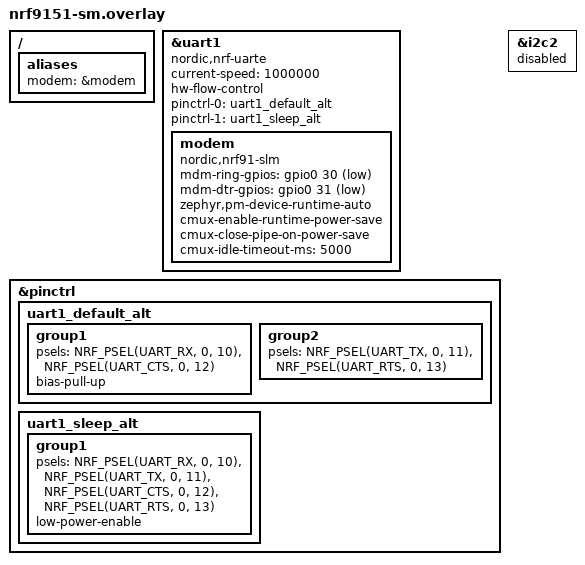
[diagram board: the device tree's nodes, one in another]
/*
 * Copyright (c) 2026 Nordic Semiconductor ASA
 *
 * SPDX-License-Identifier: LicenseRef-Nordic-5-Clause
 */
/ {
	aliases {
		modem = &modem;
	};
};

&uart1 {
	compatible = "nordic,nrf-uarte";
	current-speed = <1000000>;
	hw-flow-control;
	status = "okay";

	pinctrl-0 = <&uart1_default_alt>;
	pinctrl-1 = <&uart1_sleep_alt>;
	pinctrl-names = "default", "sleep";

	modem: modem {
		compatible = "nordic,nrf91-slm";
		status = "okay";
		mdm-ring-gpios = <&gpio0 30 (GPIO_ACTIVE_LOW | GPIO_PULL_UP)>;
		mdm-dtr-gpios = <&gpio0 31 GPIO_ACTIVE_LOW>;
		zephyr,pm-device-runtime-auto;
		cmux-enable-runtime-power-save;
		cmux-close-pipe-on-power-save;
		cmux-idle-timeout-ms = <5000>;
	};
};

&pinctrl {
	uart1_default_alt: uart1_default_alt {
		group1 {
			psels = <NRF_PSEL(UART_RX, 0, 10)>,
				<NRF_PSEL(UART_CTS, 0, 12)>;
			bias-pull-up;
		};

		group2 {
			psels = <NRF_PSEL(UART_TX, 0, 11)>,
				<NRF_PSEL(UART_RTS, 0, 13)>;
		};
	};

	uart1_sleep_alt: uart1_sleep_alt {
		group1 {
			psels = <NRF_PSEL(UART_RX, 0, 10)>,
				<NRF_PSEL(UART_TX, 0, 11)>,
				<NRF_PSEL(UART_CTS, 0, 12)>,
				<NRF_PSEL(UART_RTS, 0, 13)>;
			low-power-enable;
		};
	};
};

/* Just for sure to disable as these are in 30/31 pins where pwr pin is */
arduino_i2c: &i2c2 {
	status = "disabled";
};
